# A64 register map
Vendor: Allwinner; Series: A64; File version: 0.1
CPU: CA53 0, little endian, MPU, no FPU, 0 interrupt priority bits
Registers are 32-bit, read-write, reset 0x0 unless marked. A register's access mark holds for its fields unless they carry their own. Offsets are from the block's base; [hi:lo] are bit positions; {n}, {i} and the like mark numbered series.

## PWM
Base 0x01C21400
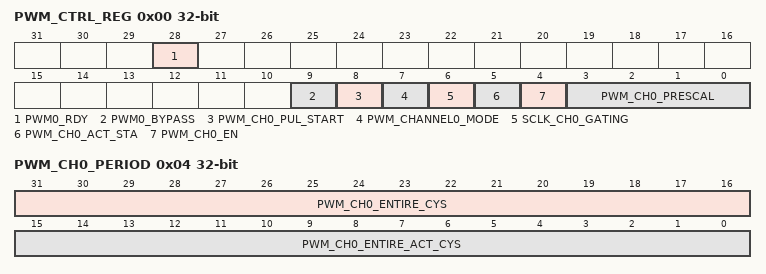
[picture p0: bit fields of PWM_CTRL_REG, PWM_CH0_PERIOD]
0x00 PWM_CTRL_REG
  [28] PWM0_RDY ro — PWM0 period register ready. 0: PWM0 period register is ready to write, 1: PWM0 period register is busy.
    0=ready (PWM0 period register is ready to write,); 1=busy (PWM0 period register is busy.)
  [9] PWM0_BYPASS — PWM CH0 bypass enable. If the bit is set to 1, PWM0`s output is OSC24MHz. 0: disable, 1: enable.
    0=disable; 1=enable
  [8] PWM_CH0_PUL_START — PWM Channel 0 pulse output start. 0: no effect, 1: output 1 pulse. The pulse width should be according to the period 0 register[15:0],and the pulse state should be according to the active state. After the pulse is finished,the bit will be cleared automatically.
    0=no_effect; 1=output 1 pulse. The pulse width should be according to the period 0 register[15:0],and the pulse state should be according to the active state. After the pulse is finished,the bit will be cleared automatically.
  [7] PWM_CHANNEL0_MODE — 0: cycle mode, 1: pulse mode.
    0=cycle mode,; 1=pulse mode
  [6] SCLK_CH0_GATING — Gating the Special Clock for PWM0(0: mask, 1: pass).
  [5] PWM_CH0_ACT_STA — PWM Channel 0 Active State. 0: Low Level, 1: High Level.
    0=Low (Low Level,); 1=High Level
  [4] PWM_CH0_EN — PWM Channel 0 Enable. 0: Disable, 1: Enable.
    0=Disable; 1=Enable
  [3:0] PWM_CH0_PRESCAL — PWM Channel 0 Prescalar. These bits should be setting before the PWM Channel 0 clock gate on. 0000: /120 0001: /180 0010: /240 0011: /360 0100: /480 0101: / 0110: / 0111: / 1000: /12k 1001: /24k 1010: /36k 1011: /48k 1100: /72k 1101: / 1110: / 1111: /1
    0=_slash_120 (/120); 1=_slash_180 (/180); 2=_slash_240 (/240); 3=_slash_360 (/360); 4=_slash_480 (/480); 8=_slash_12k (/12k); 9=_slash_24k (/24k); 10=_slash_36k (/36k); 11=_slash_48k (/48k); 12=_slash_72k (/72k); 15=_slash_1 (/1)
0x04 PWM_CH0_PERIOD reset not defined — PWM Channel 0 Period Register
  [31:16] PWM_CH0_ENTIRE_CYS — Number of the entire cycles in the PWM clock. 0 = 1 cycle 1 = 2 cycles ... N = N+1 cycles If the register need to be modified dynamically, the PCLK should be faster than the PWM CLK (PWM CLK = 24MHz/pre-scale).
  [15:0] PWM_CH0_ENTIRE_ACT_CYS — Number of the active cycles in the PWM clock. 0 = 0 cycle 1 = 1 cycles ... N = N cycles

## TWD
Base 0x01F01800
0x00 R_TWD_STATUS_REG
  [0] R_TWD_PEND_FLAG — Trusted watchdog timer`s interrupt pending. Set 1 to the bit will clear it. 0: No effect 1: Pending
    0=No_effect; 1=Pending
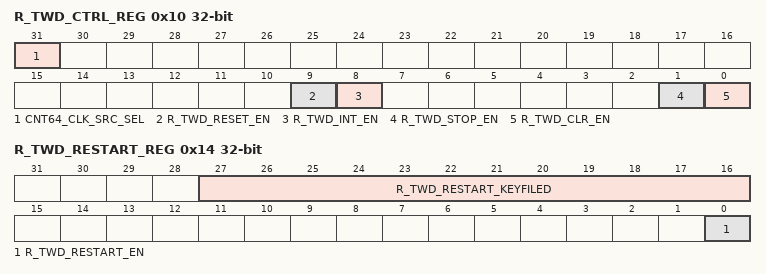
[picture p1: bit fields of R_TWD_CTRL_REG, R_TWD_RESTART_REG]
0x10 R_TWD_CTRL_REG — R_TWD Control Register
  [31] CNT64_CLK_SRC_SEL — 64-bit counter clock source select. 0: LOSC. 1: OSC24M.
    0=LOSC; 1=OSC24M
  [9] R_TWD_RESET_EN — R_TWD reset enable. 0: Reset disable. 1: Reset enable.
    0=Reset_disable; 1=Reset_enable
  [8] R_TWD_INT_EN — R_TWD Interrupt Enable. 0: Interrupt disable. 1: Interrupt enable.
    0=Interrupt_disable; 1=Interrupt_enable
  [1] R_TWD_STOP_EN — R_TWD stop enable. 0: Resume rolling-over. 1: Stop rolling-over.
    0=Resume rolling-over; 1=Stop rolling-over
  [0] R_TWD_CLR_EN — R_TWD clear enable. 0: No effect. 1: To clear relevant registers and it will change to zero after the registers are cleared.
    0=No_effect; 1=To clear relevant registers and it will change to zero after the registers are cleared
0x14 R_TWD_RESTART_REG
  [27:16] R_TWD_RESTART_KEYFILED wo — Should be written at value 0xD14. Writing any other value in this field aborts the write operation.
  [0] R_TWD_RESTART_EN wo — If writing `1` in this bit, the value of would change. 0: No effect. 1: Restart enable.
    0=No_effect; 1=Restart enable
0x20 R_TWD_LOW_CNT_REG
  [31:0] R_TWD_LOW_CNT ro — The TWD low 32-bit counter.
0x24 R_TWD_HIGH_CNT_REG
  [31:0] R_TWD_HIGH_CNT ro — The TWD high 32-bit counter.
0x30 R_TWD_INTV_VAL_REG — R_TWD Interval Value Register
  [31:0] R_TWD_INTV_VAL — The TWD interval value.
0x40 R_TWD_LOW_CNT_CMP_REG
  [31:0] R_TWD_LOW_CMP ro — The TWD low 32-bit compare counter.
0x44 R_TWD_HIGH_CNT_CMP_REG
  [31:0] R_TWD_HIGH_CMP ro — The TWD high 32-bit compare counter.
0x100 SST_NV_CNT_REG
  [31:0] SST_NV_CNT — This counter protects the trusted world Secure Storage file from replay attacks.
{0x110+4i} SYN_DATA_CNT_REG{i} (i=0..3)
  [31:0] SYN_DATA_CNT{i} — This counter is used for synchronizing data stores against replay attacks.

## SPC
Base 0x01C23400
{0x4+0xC*i} SPC_DECPORT{i}_STA_REG (i=0..2) — SPC Decode Port{i} Status Register
  [7:0] STA_DEC_PROT{i}_OUT ro — Show the status of the decode protection output: 0: = Decode region corresponding to the bit is secure 1: = Decode region corresponding to the bit is non-secure. There is one bit of the register for each protection output (See the SPC Configuration in detail).
{0x8+0xC*i} SPC_DECPORT{i}_SET_REG (i=0..2) — SPC Decode Port{i} Set Register
  [7:0] SET_DEC_PORT{i}_OUT wo — Sets the corresponding decode protection output: 0: = No effect 1: = Set decode region to non-secure. There is one bit of the register for each protection output (See the SPC Configuration in detail).
{0xC+0xC*i} SPC_DECPORT{i}_CLR_REG (i=0..2) — SPC Decode Port{i} Clear Register
  [7:0] CLR_DEC_PROT{i}_OUT wo — Clears the corresponding decode protection output: 0: = No effect 1: = Set decode region to secure. There is one bit of the register for each protection output (See the SPC Configuration in detail).
{0x4+0xC*i} SPC_DECPORT{i}_STA_REG (i=3..5) — SPC Decode Port{i} Status Register
  [7:0] STA_DEC_PROT{i}_OUT ro — Show the status of the decode protection output: 0: = Decode region corresponding to the bit is secure 1: = Decode region corresponding to the bit is non-secure There is one bit of the register for each protection output (See the SPC Configuration in detail).
{0x8+0xC*i} SPC_DECPORT{i}_SET_REG (i=3..5) — SPC Decode Port{i} Set Register
  [7:0] SET_DEC_PORT{i}_OUT wo — Sets the corresponding decode protection output: 0: = No effect 1: = Set decode region to non-secure There is one bit of the register for each protection output (See the SPC Configuration in detail).
{0xC+0xC*i} SPC_DECPORT{i}_CLR_REG (i=3..5) — SPC Decode Port{i} Clear Register
  [7:0] CLR_DEC_PROT{i}_OUT wo — Clears the corresponding decode protection output: 0: = No effect 1: = Set decode region to secure There is one bit of the register for each protection output (See the SPC Configuration in detail).

## SPINLOCK
Base 0x01C18000
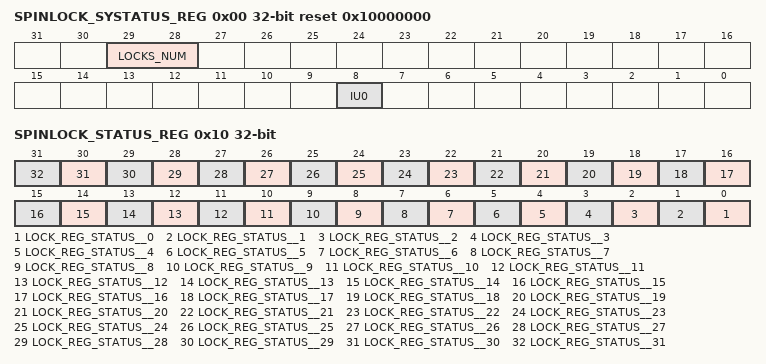
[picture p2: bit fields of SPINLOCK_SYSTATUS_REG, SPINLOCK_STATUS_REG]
0x00 SPINLOCK_SYSTATUS_REG reset 0x10000000 — Spinlock System Status Register
  [29:28] LOCKS_NUM ro — Number of lock registers implemented. 0x1: This instance has 32 lock registers. 0x2: This instance has 64 lock registers. 0x3: This instance has 128 lock registers. 0x4: This instance has 256 lock registers.
    1=This instance has 32 lock registers; 2=This instance has 64 lock registers; 3=This instance has 128 lock registers; 4=This instance has 256 lock registers
  [8] IU0 ro — In-Use flag0, covering lock register0-31. 0: All lock register 0-31 are in the Not Taken state. 1: At least one of the lock register 0-31 is in the Taken state.
    0=All (All lock register 0-31 are in the Not Taken state.); 1=At (At least one of the lock register 0-31 is in the Taken state.)
0x10 SPINLOCK_STATUS_REG — Spinlock Status Register
  [n] LOCK_REG_STATUS__{n} ro (n=0..31) — SpinLock[i] status (i=0~31) 0: The Spinlock is free, 1: The Spinlock is taken.
{0x100+4i} SPINLOCKN_LOCK_REG[{i}] (i=0..31) — SPINLOCKN_LOCK_REG[{i}]
  [0] TAKEN — Lock State. Read 0x0: The lock was previously Not Taken (free).The requester is granted the lock. Write 0x0: Set the lock to Not Taken (free). Read 0x1: The lock was previously Taken. The requester is not granted the lock and must retry. Write 0x1: No update to the lock value.
